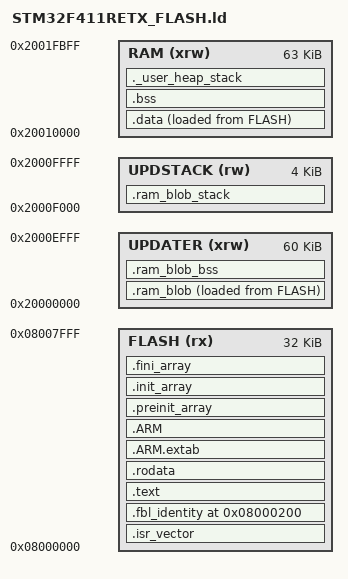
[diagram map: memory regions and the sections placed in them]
/*
******************************************************************************
**
** @file        : LinkerScript.ld
**
** @author      : Auto-generated by STM32CubeIDE
**
**  Abstract    : Linker script for NUCLEO-F411RE Board embedding STM32F411RETx Device from stm32f4 series
**                      512KBytes FLASH
**                      128KBytes RAM
**
**                Set heap size, stack size and stack location according
**                to application requirements.
**
**                Set memory bank area and size if external memory is used
**
**  Target      : STMicroelectronics STM32
**
**  Distribution: The file is distributed as is, without any warranty
**                of any kind.
**
******************************************************************************
** @attention
**
** Copyright (c) 2024 STMicroelectronics.
** All rights reserved.
**
** This software is licensed under terms that can be found in the LICENSE file
** in the root directory of this software component.
** If no LICENSE file comes with this software, it is provided AS-IS.
**
******************************************************************************
*/

/* Entry Point */
ENTRY(Reset_Handler)

/* Highest address of the user mode stack */

_Min_Heap_Size = 0x200; /* required amount of heap */
_Min_Stack_Size = 0x200; /* required amount of stack */

/* Memories definition */
MEMORY
{
  UPDATER (xrw) : ORIGIN = 0x20000000, LENGTH = 60K
  UPDSTACK (rw) : ORIGIN = 0x2000F000, LENGTH = 4K
  RAM    (xrw)    : ORIGIN = 0x20010000,   LENGTH = 63K
  FLASH  (rx)     : ORIGIN = 0x08000000,   LENGTH = 32K
}

_estack = ORIGIN(RAM) + LENGTH(RAM); /* end of "RAM" Ram type memory */



/* Sections */

SECTIONS
{
  /* The startup code into "FLASH" Rom type memory */
  .isr_vector :
  {
    . = ALIGN(4);
    KEEP(*(.isr_vector)) /* Startup code */
    . = ALIGN(4);
  } >FLASH

  .fbl_identity 0x08000200 :
  {
    KEEP(*(.fbl_identity))
  } > FLASH
  ASSERT(SIZEOF(.isr_vector) <= 512, "Resident vectors overlap image identity")
  ASSERT(SIZEOF(.fbl_identity) == 32, "Missing resident image identity")

  /* The program code and other data into "FLASH" Rom type memory */
  .text :
  {
    . = ALIGN(4);
    *(.text)           /* .text sections (code) */
    *(.text*)          /* .text* sections (code) */
    *(.glue_7)         /* glue arm to thumb code */
    *(.glue_7t)        /* glue thumb to arm code */
    *(.eh_frame)

    KEEP (*(.init))
    KEEP (*(.fini))

    . = ALIGN(4);
    _etext = .;        /* define a global symbols at end of code */
  } >FLASH

  /* Constant data into "FLASH" Rom type memory */
  .rodata :
  {
    . = ALIGN(4);
    *(.rodata)         /* .rodata sections (constants, strings, etc.) */
    *(.rodata*)        /* .rodata* sections (constants, strings, etc.) */
    . = ALIGN(4);
  } >FLASH

  .ARM.extab   : {
    . = ALIGN(4);
    *(.ARM.extab* .gnu.linkonce.armextab.*)
    . = ALIGN(4);
  } >FLASH

  .ARM : {
    . = ALIGN(4);
    __exidx_start = .;
    *(.ARM.exidx*)
    __exidx_end = .;
    . = ALIGN(4);
  } >FLASH

  .preinit_array     :
  {
    . = ALIGN(4);
    PROVIDE_HIDDEN (__preinit_array_start = .);
    KEEP (*(.preinit_array*))
    PROVIDE_HIDDEN (__preinit_array_end = .);
    . = ALIGN(4);
  } >FLASH

  .init_array :
  {
    . = ALIGN(4);
    PROVIDE_HIDDEN (__init_array_start = .);
    KEEP (*(SORT(.init_array.*)))
    KEEP (*(.init_array*))
    PROVIDE_HIDDEN (__init_array_end = .);
    . = ALIGN(4);
  } >FLASH

  .fini_array :
  {
    . = ALIGN(4);
    PROVIDE_HIDDEN (__fini_array_start = .);
    KEEP (*(SORT(.fini_array.*)))
    KEEP (*(.fini_array*))
    PROVIDE_HIDDEN (__fini_array_end = .);
    . = ALIGN(4);
  } >FLASH

  /* ELC-style copyable image: vectors first; all essential state in its own SRAM. */
  .ram_blob : ALIGN(512)
  {
    __ram_blob_vma_start = .;
    KEEP(*(.ram_blob_vectors))
    *(.ram_blob_text*)
    *(.ram_blob_data*)
    . = ALIGN(4);
    __ram_blob_vma_end = .;
  } > UPDATER AT> FLASH
  __ram_blob_load_start = LOADADDR(.ram_blob);
  __ram_blob_load_end = LOADADDR(.ram_blob) + SIZEOF(.ram_blob);
  .ram_blob_bss (NOLOAD) : ALIGN(8)
  {
    __ram_blob_bss_start = .;
    *(.ram_blob_bss*)
    __ram_blob_bss_end = .;
  } > UPDATER
  .ram_blob_stack (NOLOAD) :
  {
    __ram_blob_stack_bottom = .;
    . += 4096;
    __ram_blob_stack_top = .;
  } > UPDSTACK
  ASSERT((__ram_blob_vma_start & 511) == 0, "RAM VTOR alignment")
  ASSERT(__ram_blob_vma_start == 0x20000000, "RAM vector origin")
  ASSERT(__ram_blob_bss_end <= ORIGIN(UPDSTACK), "RAM blob/state overlaps stack")
  ASSERT(__ram_blob_stack_top == 0x20010000, "RAM stack geometry")
  ASSERT(__ram_blob_load_end <= ORIGIN(FLASH)+LENGTH(FLASH), "FBL image overflow")

  /* Used by the startup to initialize data */
  _sidata = LOADADDR(.data);

  /* Initialized data sections into "RAM" Ram type memory */
  .data :
  {
    . = ALIGN(4);
    _sdata = .;        /* create a global symbol at data start */
    *(.data)           /* .data sections */
    *(.data*)          /* .data* sections */
    *(.RamFunc)        /* .RamFunc sections */
    *(.RamFunc*)       /* .RamFunc* sections */

    . = ALIGN(4);
    _edata = .;        /* define a global symbol at data end */

  } >RAM AT> FLASH

  /* Uninitialized data section into "RAM" Ram type memory */
  . = ALIGN(4);
  .bss :
  {
    /* This is used by the startup in order to initialize the .bss section */
    _sbss = .;         /* define a global symbol at bss start */
    __bss_start__ = _sbss;
    *(.bss)
    *(.bss*)
    *(COMMON)

    . = ALIGN(4);
    _ebss = .;         /* define a global symbol at bss end */
    __bss_end__ = _ebss;
  } >RAM

  /* User_heap_stack section, used to check that there is enough "RAM" Ram  type memory left */
  ._user_heap_stack :
  {
    . = ALIGN(8);
    PROVIDE ( end = . );
    PROVIDE ( _end = . );
    . = . + _Min_Heap_Size;
    . = . + _Min_Stack_Size;
    . = ALIGN(8);
  } >RAM

  /* Remove information from the compiler libraries */
  /DISCARD/ :
  {
    libc.a ( * )
    libm.a ( * )
    libgcc.a ( * )
  }

  .ARM.attributes 0 : { *(.ARM.attributes) }
}
